# VDMA_ICONT register map
Vendor: Texas Instruments
Peripheral module from a debugger description file (folder DRA74xP_75xP_76xP_77xP).
Registers are 32-bit, read-write, no defined reset value unless marked. A register's access mark holds for its fields unless they carry their own. Offsets are as the file gives them; lines under a group give offsets from that group; [hi:lo] are bit positions; {n}, {i} and the like mark numbered series; 'fields as' and 'values as' point back to an identical list; <NAME> marks a mode.

## VDMA_ICONT
0x00 VDMA_REVISION ro — IP revision identifier.
  [31:0] REVISION — IP Revision
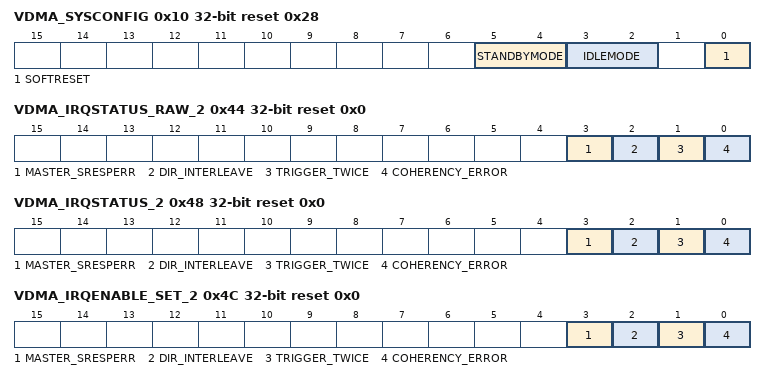
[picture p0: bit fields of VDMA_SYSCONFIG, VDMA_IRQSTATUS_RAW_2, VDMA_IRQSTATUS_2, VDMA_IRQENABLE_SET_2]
0x10 VDMA_SYSCONFIG access per field reset 0x28 — Clock management configuration
  [5:4] STANDBYMODE rw — Configuration of the local initiator state management mode. By definition, initiator can generate read/write transaction as long as it is out of STANDBY state.
    0=Force-standby mode: local initiator is unconditionally placed in standby state; 1=No-standby mode: local initiator is unconditionally placed out of standby state; 2=Smart-standby mode: local initiator standby status depends on local conditions, that is, the module's functional requirement from the initiator; 3=Smart-standby wakeup-capable mode: local initiator standby status depends on local conditions, that is, the module's functional requirement from the initiator
  [3:2] IDLEMODE rw — Configuration of the local target state management mode. By definition, target can handle read/write transaction as long as it is out of IDLE state.
    0=N/A; 1=N/A; 2=Smart-idle mode: local target's idle state eventually follows (acknowledges) the system's idle requests, depending on the IP module's internal requirements; 3=N/A
  [0] SOFTRESET rw — Software reset. Read 0: Software reset done, no pending action Write 0: No action Write 1: Initiate software reset Read 1: Software reset ongoing
0x20 VDMA_IRQ_EOI wo reset 0x0 — End Of Interrupt number specification
  [7:0] LINE_NUMBER — Software End Of Interrupt (EOI) control. Write number of interrupt output. Write 0x0: EOI for interrupt output line #0 Write 0x1: EOI for interrupt output line #1 Write 0x2: EOI for interrupt output line #2 Write 0x3: N/A Write 0x4: N/A Write 0x5: N/A Write 0x6: N/A Write 0x7: N/A
0x24 VDMA_IRQSTATUS_RAW_0 access not given reset 0x0 — Per-end of group (31 down to 0) internal signaling raw interrupt status vector, line #0. Raw status is set even if end of group (31 down to 0) interrupt is not enabled. Write 1 to set the (raw) status, mostly for debug.
  [31:0] ICONT1_END_GROUP31_0 — Settable raw status for port1 end of group 31 to 0 Write 0: No action Read 0: No event pending Read 1: Event pending Write 1: Set event (debug) (access RW W1toSet)
0x28 VDMA_IRQSTATUS_0 access not given reset 0x0 — Per-end of group (31 down to 0) internal signaling 'enabled' interrupt status vector, line #0. Enabled status is not set unless event is enabled. Write 1 to clear the status after interrupt has been serviced (raw status gets cleared, that is, even if not enabled).
  [31:0] ICONT1_END_GROUP31_0 — Write 0: No action Read 0: No (enabled) event pending Read 1: Event pending Write 1: Clear (raw) event (access RW W1toClr)
0x2C VDMA_IRQENABLE_SET_0 access not given reset 0x0 — Per-end of group (31 down to 0) internal event interrupt enable bit vector, line #0. Write 1 to set (enable interrupt). Readout equal to corresponding _CLR register.
  [31:0] ENABLE_SET_ICONT1_GROUP31_0 — Enable for end_of_port1_group31 to 0 interrupts Write 0: No action Read 0: Interrupt disabled (masked) Read 1: Interrupt enabled Write 1: Enable interrupt (access RW W1toSet)
0x30 VDMA_IRQENABLE_CLR_0 access not given reset 0x0 — Per-end of group (31 down to 0) internal event interrupt enable bit vector, line #0. Write 1 to clear (disable interrupt). Readout equal to corresponding _SET register.
  [31:0] ENABLE_CLR_ICONT1_GROUP31_0 — Write 0: No action Read 0: Interrupt disabled (masked) Read 1: Interrupt enabled Write 1: Disable interrupt (access RW W1toClr)
0x34 VDMA_IRQSTATUS_RAW_1 access not given reset 0x0 — Per-end of group (31 down to 0) internal signaling raw interrupt status vector, line #1. Raw status is set even if event is not enabled. Write 1 to set the (raw) status, mostly for debug.
  [31:0] ICONT2_END_GROUP31_0 — Settable raw status for port2 end of group 31 to 0 Write 0: No action Read 0: No event pending Read 1: Event pending Write 1: Set event (debug) (access RW W1toSet)
0x38 VDMA_IRQSTATUS_1 access not given reset 0x0 — Per-end of group (31 down to 0) internal signaling 'enabled' interrupt status vector, line #1. Enabled status is not set unless event is enabled. Write 1 to clear the status after interrupt has been serviced (raw status gets cleared, that is, even if not enabled).
  [31:0] ICONT2_END_GROUP31_0 — Write 0: No action Read 0: No (enabled) event pending Read 1: Event pending Write 1: Clear (raw) event (access RW W1toClr)
0x3C VDMA_IRQENABLE_SET_1 access not given reset 0x0 — Per-end of group (31 down to 0) internal event interrupt enable bit vector, line #1. Write 1 to set (enable interrupt). Readout equal to corresponding _CLR register.
  [31:0] ENABLE_SET_ICONT2_GROUP31_0 — Enable for end_of_group31 to 0 interrupts Write 0: No action Read 0: Interrupt disabled (masked) Read 1: Interrupt enabled Write 1: Enable interrupt (access RW W1toSet)
0x40 VDMA_IRQENABLE_CLR_1 access not given reset 0x0 — Per-end of group (31 down to 0) internal event interrupt enable bit vector, line #1. Write 1 to clear (disable interrupt). Readout equal to corresponding _SET register.
  [31:0] ENABLE_CLR_ICONT2_GROUP31_0 — Write 0: No action Read 0: Interrupt disabled (masked) Read 1: Interrupt enabled Write 1: Disable interrupt (access RW W1toClr)
0x44 VDMA_IRQSTATUS_RAW_2 access not given reset 0x0 — Per-error event raw interrupt status vector, line #2. Raw status is set even if event is not enabled. Write 1 to set the (raw) status, mostly for debug. Write 0: No action Read 0: No evt pend. Read 1: Event pend. Write 1: Set event
  [3] MASTER_SRESPERR — Interrupt fires when one VDMA OCP master port (SL2R, SL2W, or L3_MAIN) received Sresp=ERR from platform. Note that corresponding context does (did) not abort corresponding transaction neither corresponding group transfer and does (did) not re-submit transaction. (access RW W1toSet)
  [2] DIR_INTERLEAVE — Interrupt fires (if enabled) in case U/V bit is set and DIR field is different from 0b10. (access RW W1toSet)
  [1] TRIGGER_TWICE — From software user perspective: interrupt fires when same group has been triggered twice without having received end of corresponding group signaling in between. From hardware design perspective the actual condition for this interrupt to fire is that same group trigger has been pushed twice in trigger queue, without the first one being popped out of queue in between. Note that this error signalling does not contain the faulty group Id information. (access RW W1toSet)
  [0] COHERENCY_ERROR — Interrupt fires (if enabled) in case descriptors pushed into lists (either asynchronous or synchronous) do not match with current group being scheduled. Reasons that can generate such a situation are: - several hosts 'concurrently' write descriptors through configuration port, without synchronisation between each other; since interconnect does not ensure initiator atomicity, this might lead to group interleaved descriptors into non deterministic descriptor FIFO - 'blocks' of descriptors to be pushed through transversal port might have been improperly prepared and then potentially contain several interleaved groups - same comment as above for deterministic memory configuration. (access RW W1toSet)
0x48 VDMA_IRQSTATUS_2 access not given reset 0x0 — Per-error event 'enabled' interrupt status vector, line #2. Enabled status is not set unless event is enabled. Write 1 to clear the status after interrupt has been serviced (raw status gets cleared, ithat is, even if not enabled). Write 0: No action Read 0: No (enabled) event pending Read 1: Event pending Write 1: Clear (raw) event
  [3] MASTER_SRESPERR — Interrupt fires when one VDMA OCP master port (SL2R, SL2W, or L3_MAIN) received Sresp=ERR from platform. Note that corresponding context does (did) not abort corresponding transaction neither corresponding group transfer and does (did) not re-submit transaction. (access RW W1toClr)
  [2] DIR_INTERLEAVE — Interrupt fires (if enabled) in case U/V bit is set and DIR field is different from 0b10. (access RW W1toClr)
  [1] TRIGGER_TWICE — From software user perspective: interrupt fires when same group has been triggered twice without having received end of corresponding group signaling in between. From hardware design perspective the actual condition for this interrupt to fire is that same group trigger has been pushed twice in trigger queue, without the first one being popped out of queue in between. Note that this error signalling does not contain the faulty group Id information. (access RW W1toClr)
  [0] COHERENCY_ERROR — Interrupt fires (if enabled) in case descriptors pushed into lists (either asynchronous or synchronous) do not match with current group being scheduled. Reasons that can generate such a situation are: - several hosts 'concurrently' write descriptors through configuration port, without synchronisation between each other; since interconnect does not ensure initiator atomicity, this might lead to group interleaved descriptors into non deterministic descriptor FIFO - 'blocks' of descriptors to be pushed through transversal port migth have been improperly prepared and then potentially contain several interleaved groups - same comment as above for deterministic memory configuration. (access RW W1toClr)
0x4C VDMA_IRQENABLE_SET_2 access not given reset 0x0 — Per-error event interrupt enable bit vector, line #2. Write 1 to set (enable interrupt). Readout equal to corresponding _CLR register. Enable for end_of_group31 to 0 interrupts Write 0: No action Read 0: Interrupt disabled (masked) Read 1: Interrupt enabled Write 1: Enable interrupt
  [3] MASTER_SRESPERR — (access RW W1toSet)
  [2] DIR_INTERLEAVE — (access RW W1toSet)
  [1] TRIGGER_TWICE — (access RW W1toSet)
  [0] COHERENCY_ERROR — (access RW W1toSet)
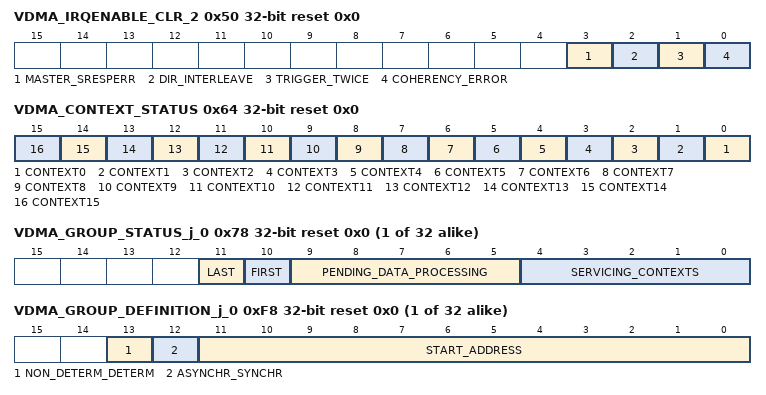
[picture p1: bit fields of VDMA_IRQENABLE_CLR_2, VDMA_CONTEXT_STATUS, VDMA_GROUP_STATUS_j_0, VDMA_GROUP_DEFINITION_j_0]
0x50 VDMA_IRQENABLE_CLR_2 access not given reset 0x0 — Per-error event interrupt enable bit vector, line #2. Write 1 to clear (disable interrupt). Readout equal to corresponding _SET register. Write 0: No action Read 0: Interrupt disabled (masked) Read 1: Interrupt enabled Write 1: Disable interrupt
  [3] MASTER_SRESPERR — (access RW W1toClr)
  [2] DIR_INTERLEAVE — (access RW W1toClr)
  [1] TRIGGER_TWICE — (access RW W1toClr)
  [0] COHERENCY_ERROR — (access RW W1toClr)
0x54 VDMA_SYNCHR_LIST_LEVEL ro reset 0x0
  [3:0] LEVEL — Indicates number of pending (that is, which have been pushed into and wait for breakdown logic to pick them from list) entries of synchronous transfer list. One entry contains one uniquified format descriptor.
0x58 VDMA_ASYNCHR_LIST_LEVEL ro reset 0x0
  [3:0] LEVEL — Indicates number of pending (that is, which have been pushed into and wait for breakdown logic to pick them from list) entries of asynchronous transfer list. One entry contains one uniquified format descriptor.
0x5C VDMA_NON_DETERM_FIFO_LEVEL ro reset 0x0
  [7:0] LEVEL — Indicates number of pending (that is, which have been pushed into and wait for read address generator to pick them from list) entries of nondeterministic object descriptor FIFO. Note that it does not reflect the number of descriptors present into this FIFO given there can be short and/or long descriptors. Bit field size TBC
0x60 VDMA_TBA access per field reset 0x0 — TILER address mapping. This register shall only be set statically, that is, at early VDMA configuration time, before any transfer is ever triggered.
  [2:0] OCP_3MSB rw
0x64 VDMA_CONTEXT_STATUS ro reset 0x0 — When individual bit is reset, corresponding context is available. When individual bit is set, corresponding context is allocated.
  [n] CONTEXT{n} (n=0..15)
0x68 VDMA_GROUP_TRIGGER wo reset 0x0 — Register entry for software user to trigger deterministic (only) groups through CPU writes. Write '1' to desired bit triggers corresponding group (which SHALL be defined as deterministic through GROUP_DEFINITION register set). Writing '1' to a group defined as non deterministic leads to VDMA undefined behavior. write '0' has no effect.
  [31:0] CPU_TRIGGER_GROUP0_31 — MS bit applies to group 31 LS bit applies to Group 0
0x6C VDMA_MAX_CONTEXT_SYNCHR access per field reset 0xF — Software user configurable maximum number of context synchronous list can get benefit of. This register should only be set statically, that is, at early VDMA configuration time, before any transfer is ever triggered. Should it be set with another value at run time, software user shall ensure that there is no pending trigger, no pending descriptors in nondeterministic FIFO, no pending descriptors in asynchronous nor synchronous list and no pending transactions on master ports.
  [3:0] MAX_VALUE rw — (max_value + 1) is the actual number of context allocatable to synchronous list.
0x70 VDMA_MAX_CONTEXT_ASYNCHR access per field reset 0x0 — Software user configurable maximum number of context asynchronous list can get benefit of. This register should only be set statically, that is, at early VDMA configuration time, before any transfer is ever triggered. Should it be set with another value at run time, software user shall ensure that there is no pending trigger, no pending descriptors in nondeterministic FIFO, no pending descriptors in asynchronous nor synchronous list and no pending transactions on master ports.
  [3:0] MAX_VALUE rw — (max_value + 1) is the actual number of context allocatable to asynchronous list.
0x74 VDMA_IRQ_NEOG reset 0x0 — Sets whether end of group signaling should be set through external hardware lines (like the deterministic group triggers) or wrap into interrupt line.
  [31:0] IRQ_NEOG_GROUP31_0 — when set, corresponding end of group signaling is propagated as interrupt source to both interrupt line 0 and 1. Software user is expected in that case to enable corresponding interrupt. When reset, corresponding end of group signaling is propagated to end of group port.
{0x78+4i} VDMA_GROUP_STATUS_j_{i} ro reset 0x0 (i=0..31)
  [11] LAST — When set, means that last breakdown of last descriptor of group has been attributed to one context. Bit is automatically cleared by hardware when group transfer completes.
  [10] FIRST — When set, means that first breakdown of first descriptor of group has been attributed to one context. Bit is automatically cleared by hardware when group transfer completes.
  [9:5] PENDING_DATA_PROCESSING — Current number of data chunks (each of 128bytes max) that will require some data processing. Which kind of processing is not reflected.
  [4:0] SERVICING_CONTEXTS — Number of contexts currently allocated to service this group.
{0xF8+4i} VDMA_GROUP_DEFINITION_j_{i} access per field reset 0x0 (i=0..31) — Group_definition register set is the software user entry to define groups mapping and routing into and through event engine: - throw group into synchronous or asynchronous list - pick descriptors from nondeterministic or deterministic memory - start address of descriptors when belonging to a deterministic group.
  [13] NON_DETERM_DETERM rw — Group is made of nondeterministic object descriptors when reset, and of deterministic object descriptors when set.
  [12] ASYNCHR_SYNCHR rw — When reset indicates that this (these) group descriptor(s) are to be pushed into asynchronous transfer queue, when set into synchronous transfer queue.
  [11:0] START_ADDRESS rw — In case of deterministic transfers shall be the very first descriptor address of group. Note that this field shall be filled-in with the 12 least significant bits of VDMA_L_DETERM_31_0_i address offsets (X being the one among 128 entry that contains the first descriptor of considered group). In case of nondeterministic transfer this field is N/A
{0x178+4i} VDMA_NON_DETERM_k_{i} wo reset 0x0 (i=0..3) — Non deterministic descriptor FIFO width being 128b and configuration port width being 32b, four OCP write commands into four different (incremental) addresses to create one (short) nondeterministic descriptor. Least significant 32b word of (short) descriptor shall be written at 0x178h. Most significant 32b word of (short) descriptor shall be written at 0x184h. Write command order has no importance. When a long descriptor is required, four write commands (above) sequence should be repeated. Note that the first four write command sequence shall set the most significant 128b of the 256b descriptor to respect the requirement of pushing the 128b part containing the descriptor header field first.
  [31:0] ONE_OUT_OF_FOUR_32B_WORD — if address offset is 0x0178h data will be mapped into descriptor entry bits [31..0] if address offset is 0x017Ch data will be mapped into descriptor entry bits [63..32] if address offset is 0x0180h data will be mapped into descriptor entry bits [95..64] if address offset is 0x0184h data will be mapped into descriptor entry bits [127..96]
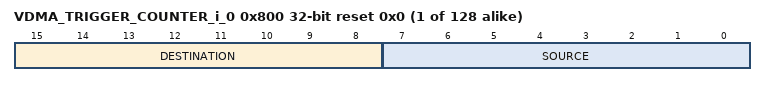
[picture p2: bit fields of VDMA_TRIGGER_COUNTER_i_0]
{0x800+4i} VDMA_TRIGGER_COUNTER_i_{i} wo reset 0x0 (i=0..127)
  [15:8] DESTINATION — Byte slot to write intended counter value to start with for the destination side of the transfer. Note that when corresponding (same index) deterministic descriptor is written (even partially) the destination (and the source) trigger counter is automatically reset to 0 by hardware.
  [7:0] SOURCE — Byte slot to write intended counter value to start with for the source side of the transfer. Note that when corresponding (same index) deterministic descriptor is written (even partially) the source (and the destination) trigger counter is automatically reset to 0 by hardware.
{0x1000+0x20*i} VDMA_L_DETERM_31_0_i_{i} (i=0..127) — Least significant 32b word of deterministic memory 128b word entry of least significant 128b word of 256b descriptor
  [31:0] DESCRIPTOR_BITS_31_TO_0 — Least significant 32b word of 256b word deterministic descriptor
{0x1004+0x20*i} VDMA_L_DETERM_63_32_i_{i} (i=0..127) — 32b word positioned at bits [63..32] in deterministic memory 128b word entry of least significant 128b word of 256b descriptor
  [31:0] DESCRIPTOR_BITS_63_TO_32 — bits [63..32] of 256b word deterministic descriptor
{0x1008+0x20*i} VDMA_L_DETERM_95_64_i_{i} (i=0..127) — 32b word positioned at bits 95 to 64 in deterministic memory 128b word entry of least significant 128b word of 256b descriptor
  [31:0] DESCRIPTOR_BITS_95_TO_64 — bits [95..64] of 256b word deterministic descriptor
{0x100C+0x20*i} VDMA_L_DETERM_127_96_i_{i} (i=0..127) — 32b word positioned at bits 127 to 96 in deterministic memory 128b word entry of least significant 128b word of 256b descriptor
  [31:0] DESCRIPTOR_BITS_127_TO_96 — bits [127..96] of 256b word deterministic descriptor
{0x1010+0x20*i} VDMA_H_DETERM_31_0_i_{i} (i=0..127) — Least significant 32b word of deterministic memory 128b word entry of most significant 128b word of 256b descriptor
  [31:0] DESCRIPTOR_BITS_159_TO_128 — bits [159..128] of 256b word deterministic descriptor
{0x1014+0x20*i} VDMA_H_DETERM_63_32_i_{i} (i=0..127) — 32b word positioned at bits [63..32] in deterministic memory 128b word entry of most significant 128b word of 256b descriptor
  [31:0] DESCRIPTOR_BITS_191_TO_160 — bits [191..160] of 256b word deterministic descriptor
{0x1018+0x20*i} VDMA_H_DETERM_95_64_i_{i} (i=0..127) — 32b word positioned at bits 95 to 64 in deterministic memory 128b word entry of most significant 128b word of 256b descriptor
  [31:0] DESCRIPTOR_BITS_223_TO_192 — bits [223..192] of 256b word deterministic descriptor
{0x101C+0x20*i} VDMA_H_DETERM_127_96_i_{i} (i=0..127) — 32b word positioned at bits 127 to 96 in deterministic memory 128b word entry of most significant 128b word of 256b descriptor
  [31:0] DESCRIPTOR_BITS_255_TO_224 — bits [255..224] of 256b word deterministic descriptor
